# ATSAMR30 register map
Vendor: Atmel Corporation; Series: SAMR30; File version: B
Atmel ATSAMR30 devices
CPU: CM0+ r0p1, little endian, no MPU, no FPU, VTOR, 2 interrupt priority bits
Registers are 32-bit, read-write, reset 0x0 unless marked. A register's access mark holds for its fields unless they carry their own. Offsets are from the block's base; lines under a group give offsets from that group; [hi:lo] are bit positions; {n}, {i} and the like mark numbered series; 'fields as' and 'values as' point back to an identical list; <NAME> marks a mode.

## Memory map
0x40000000 PM size 0x80 — Power Manager
0x40000400 MCLK size 0x80 — Main Clock
0x40000800 RSTC size 0x20 — Reset Controller
0x40000C00 OSCCTRL size 0x80 — Oscillators Control
0x40001000 OSC32KCTRL size 0x80 — 32k Oscillators Control
0x40001400 SUPC size 0x80 — Supply Controller
0x40001800 GCLK size 0x200 — Generic Clock Generator
0x40001C00 WDT size 0x10 — Watchdog Timer
0x40002000 RTC size 0x80 — Real-Time Counter
0x40002400 EIC size 0x40 — External Interrupt Controller
0x40002800 PORT size 0x200 — Port Module
0x40002C00 TAL size 0x80 — Trigger Allocator
0x41000000 USB size 0x400 — Universal Serial Bus
0x41002000 DSU size 0x2000 — Device Service Unit
0x41004000 NVMCTRL size 0x80 — Non-Volatile Memory Controller
0x41006000 MTB size 0x1000 — Cortex-M0+ Micro-Trace Buffer
0x42000000 SERCOM0 size 0x40 — Serial Communication Interface 0
0x42000400 SERCOM1 size 0x40 — Serial Communication Interface 1
0x42000800 SERCOM2 size 0x40 — Serial Communication Interface 2
0x42000C00 SERCOM3 size 0x40 — Serial Communication Interface 3
0x42001000 SERCOM4 size 0x40 — Serial Communication Interface 4
0x42001400 TCC0 size 0x90 — Timer Counter Control 0
0x42001800 TCC1 size 0x90 — Timer Counter Control 1
0x42001C00 TCC2 size 0x90 — Timer Counter Control 2
0x42002000 TC0 size 0x40 — Basic Timer Counter 0
0x42002400 TC1 size 0x40 — Basic Timer Counter 1
0x43000000 EVSYS size 0x400 — Event System Interface
0x43000400 SERCOM5 size 0x40 — Serial Communication Interface 5
0x43000800 TC4 size 0x40 — Basic Timer Counter 4
0x43000C00 ADC size 0x80 — Analog Digital Converter
0x43001000 AC size 0x40 — Analog Comparators
0x43001C00 CCL size 0x40 — Configurable Custom Logic
0x44000000 PAC size 0x80 — Peripheral Access Controller
0x44000400 DMAC size 0x80 — Direct Memory Access Controller
0x60000000 PORT_IOBUS size 0x200 — Port Module (IOBUS)

## Interrupts
0 MCLK_INTREQ (MCLK)
0 OSC32KCTRL_INTREQ (OSC32KCTRL)
0 OSCCTRL_INTREQ (OSCCTRL)
0 PAC_INTREQ (PAC)
0 PM_INTREQ (PM)
0 SUPC_INTREQ (SUPC)
0 TAL_INTREQ (TAL)
1 WDT_INTREQ (WDT)
2 RTC_INTREQ (RTC)
3 EIC_INTREQ (EIC)
4 NVMCTRL_INTREQ (NVMCTRL)
5 DMAC_INTREQ (DMAC)
6 USB_INTREQ (USB)
7 EVSYS_INTREQ (EVSYS)
8 SERCOM0_INTREQ (SERCOM0)
9 SERCOM1_INTREQ (SERCOM1)
10 SERCOM2_INTREQ (SERCOM2)
11 SERCOM3_INTREQ (SERCOM3)
12 SERCOM4_INTREQ (SERCOM4)
13 SERCOM5_INTREQ (SERCOM5)
14 TCC0_INTREQ (TCC0)
15 TCC1_INTREQ (TCC1)
16 TCC2_INTREQ (TCC2)
17 TC0_INTREQ (TC0)
18 TC1_INTREQ (TC1)
21 TC4_INTREQ (TC4)
22 ADC_INTREQ (ADC)
23 AC_INTREQ (AC)

## AC — Analog Comparators
Base 0x43001000; register names take the prefix AC_
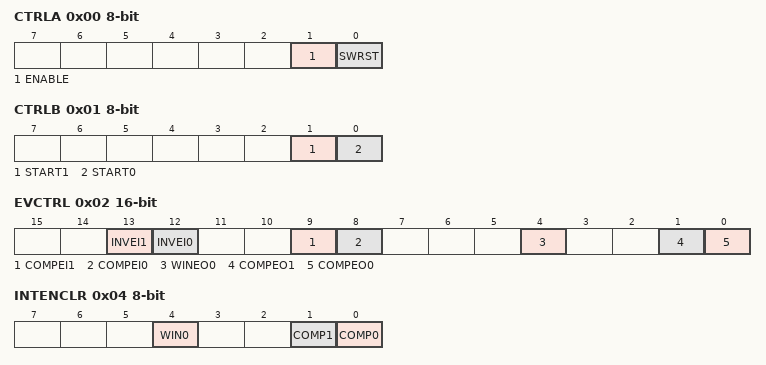
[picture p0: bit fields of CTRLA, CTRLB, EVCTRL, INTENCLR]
0x00 CTRLA 8-bit — Control A
  [1] ENABLE
  [0] SWRST wo — Software Reset
0x01 CTRLB 8-bit wo — Control B
  [1] START1 — Comparator 1 Start Comparison
  [0] START0 — Comparator 0 Start Comparison
0x02 EVCTRL 16-bit — Event Control
  [13] INVEI1 — Comparator 1 Input Event Invert Enable
  [12] INVEI0 — Comparator 0 Input Event Invert Enable
  [9] COMPEI1 — Comparator 1 Event Input Enable
  [8] COMPEI0 — Comparator 0 Event Input Enable
  [4] WINEO0 — Window 0 Event Output Enable
  [1] COMPEO1 — Comparator 1 Event Output Enable
  [0] COMPEO0 — Comparator 0 Event Output Enable
0x04 INTENCLR 8-bit — Interrupt Enable Clear
  [4] WIN0 — Window 0 Interrupt Enable
  [1] COMP1 — Comparator 1 Interrupt Enable
  [0] COMP0 — Comparator 0 Interrupt Enable
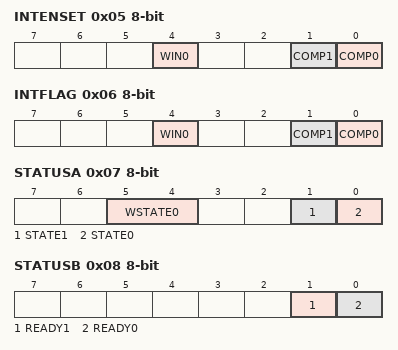
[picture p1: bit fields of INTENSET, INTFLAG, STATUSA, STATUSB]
0x05 INTENSET 8-bit — Interrupt Enable Set
  fields as INTENCLR
0x06 INTFLAG 8-bit — Interrupt Flag Status and Clear
  [4] WIN0 — Window 0
  [1] COMP1 — Comparator 1
  [0] COMP0 — Comparator 0
0x07 STATUSA 8-bit ro
  [5:4] WSTATE0 — Window 0 Current State
    0=ABOVE (Signal is above window); 1=INSIDE (Signal is inside window); 2=BELOW (Signal is below window)
  [1] STATE1 — Comparator 1 Current State
  [0] STATE0 — Comparator 0 Current State
0x08 STATUSB 8-bit ro
  [1] READY1 — Comparator 1 Ready
  [0] READY0 — Comparator 0 Ready
0x09 DBGCTRL 8-bit — Debug Control
  [0] DBGRUN — Debug Run
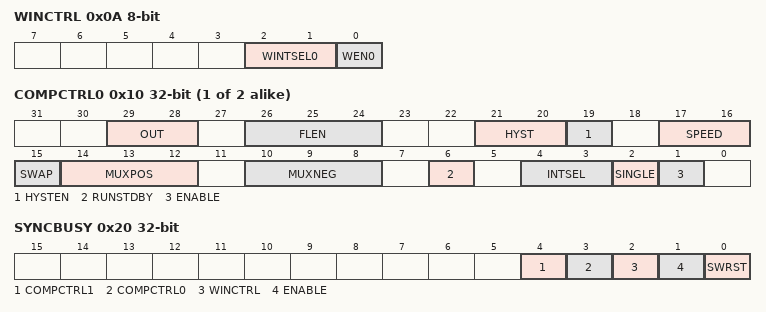
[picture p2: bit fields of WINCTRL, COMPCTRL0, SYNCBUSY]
0x0A WINCTRL 8-bit — Window Control
  [2:1] WINTSEL0 — Window 0 Interrupt Selection
    0=ABOVE (Interrupt on signal above window); 1=INSIDE (Interrupt on signal inside window); 2=BELOW (Interrupt on signal below window); 3=OUTSIDE (Interrupt on signal outside window)
  [0] WEN0 — Window 0 Mode Enable
{0xC+i} SCALER{i} (i=0..1) 8-bit — Scaler n
  [5:0] VALUE — Scaler Value
{0x10+4i} COMPCTRL{i} (i=0..1) — Comparator Control n
  [29:28] OUT — Output
    0=OFF (The output of COMPn is not routed to the COMPn I/O port); 1=ASYNC (The asynchronous output of COMPn is routed to the COMPn I/O port); 2=SYNC (The synchronous output (including filtering) of COMPn is routed to the COMPn I/O port)
  [26:24] FLEN — Filter Length
    0=OFF (No filtering); 1=MAJ3 (3-bit majority function (2 of 3)); 2=MAJ5 (5-bit majority function (3 of 5))
  [21:20] HYST — Hysteresis Level
    0=50mV; 1=70mV; 2=90mV; 3=110mV
  [19] HYSTEN — Hysteresis Enable
  [17:16] SPEED — Speed Selection
    0=LOW (Low speed); 1=MEDLOW (Medium low speed); 2=MEDHIGH (Medium high speed); 3=HIGH (High speed)
  [15] SWAP — Swap Inputs and Invert
  [14:12] MUXPOS — Positive Input Mux Selection
    {v}=PIN{v} (I/O pin {v}) (v=0..3); 4=VSCALE (VDD Scaler)
  [10:8] MUXNEG — Negative Input Mux Selection
    {v}=PIN{v} (I/O pin {v}) (v=0..3); 4=GND (Ground); 5=VSCALE (VDD scaler); 6=BANDGAP (Internal bandgap voltage)
  [6] RUNSTDBY — Run in Standby
  [4:3] INTSEL — Interrupt Selection
    0=TOGGLE (Interrupt on comparator output toggle); 1=RISING (Interrupt on comparator output rising); 2=FALLING (Interrupt on comparator output falling); 3=EOC (Interrupt on end of comparison (single-shot mode only))
  [2] SINGLE — Single-Shot Mode
  [1] ENABLE
0x20 SYNCBUSY ro — Synchronization Busy
  [4] COMPCTRL1 — COMPCTRL 1 Synchronization Busy
  [3] COMPCTRL0 — COMPCTRL 0 Synchronization Busy
  [2] WINCTRL — WINCTRL Synchronization Busy
  [1] ENABLE — Enable Synchronization Busy
  [0] SWRST — Software Reset Synchronization Busy

## Licence text in the file
============================================================================ Atmel Microcontroller Software Support ============================================================================ Copyright (c) 2016 Atmel Corporation, a wholly owned subsidiary of Microchip Technology Inc. . Licensed under the Apache License, Version 2.0 (the "License"); you may not use this file except in compliance with the License. You may obtain a copy of the Licence at http://www.apache.org/licenses/LICENSE-2.0 . Unless required by applicable law or agreed to in writing, software distributed under the License is distributed on an "AS IS" BASIS, WITHOUT WARRANTIES OR CONDITIONS OF ANY KIND, either express or implied. See the License for the specific language governing permissions and limitations under the License. ============================================================================
